# STM32G473 register map
File version: 2.8
CPU: CM4 r0p1, little endian, MPU, FPU, 4 interrupt priority bits
Registers are 32-bit, read-write, reset 0x0 unless marked. A register's access mark holds for its fields unless they carry their own. Offsets are from the block's base; [hi:lo] are bit positions; {n}, {i} and the like mark numbered series; 'fields as' and 'values as' point back to an identical list.

## ADC12_Common — Analog-to-Digital Converter
Base 0x50000300
Same registers: ADC345_Common 0x50000700
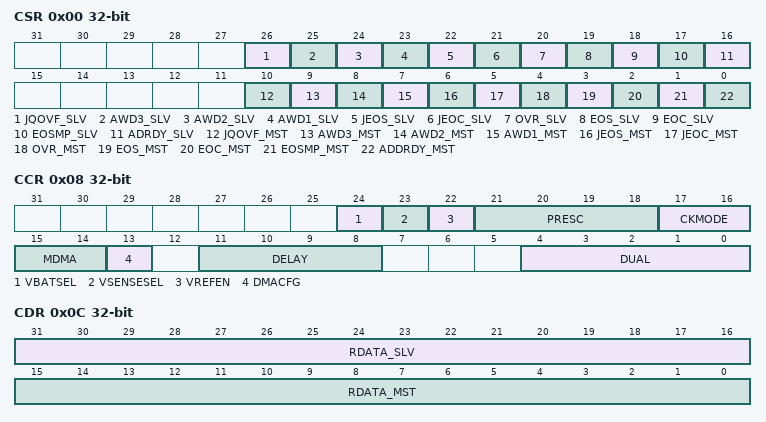
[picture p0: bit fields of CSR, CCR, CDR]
0x00 CSR ro — ADC Common status register
  [26] JQOVF_SLV — Injected Context Queue Overflow flag of the slave ADC
    0=NoOverflow (No injected context queue overflow has occurred); 1=Overflow (Injected context queue overflow has occurred)
  [25] AWD3_SLV — Analog watchdog 3 flag of the slave ADC
    0=NoEvent (No analog watchdog event occurred); 1=Event (Analog watchdog event occurred)
  [24] AWD2_SLV — Analog watchdog 2 flag of the slave ADC
    values as AWD3_SLV
  [23] AWD1_SLV — Analog watchdog 1 flag of the slave ADC
    values as AWD3_SLV
  [22] JEOS_SLV — End of injected sequence flag of the slave ADC
    0=NotComplete (Injected sequence is not complete); 1=Complete (Injected sequence complete)
  [21] JEOC_SLV — End of injected conversion flag of the slave ADC
    0=NotComplete (Injected conversion is not complete); 1=Complete (Injected conversion complete)
  [20] OVR_SLV — Overrun flag of the slave ADC
    0=No overrun occurred; 1=Overrun occurred
  [19] EOS_SLV — End of regular sequence flag of the slave ADC
    0=NotComplete (Regular sequence is not complete); 1=Complete (Regular sequence complete)
  [18] EOC_SLV — End of regular conversion of the slave ADC
    0=NotComplete (Regular conversion is not complete); 1=Complete (Regular conversion complete)
  [17] EOSMP_SLV
    0=NotEnded (End of sampling phase no yet reached); 1=Ended (End of sampling phase reached)
  [16] ADRDY_SLV
    0=NotReady (ADC is not ready to start conversion); 1=Ready (ADC is ready to start conversion)
  [10] JQOVF_MST
    values as JQOVF_SLV
  [9] AWD3_MST
    values as AWD3_SLV
  [8] AWD2_MST
    values as AWD3_SLV
  [7] AWD1_MST
    values as AWD3_SLV
  [6] JEOS_MST
    values as JEOS_SLV
  [5] JEOC_MST
    values as JEOC_SLV
  [4] OVR_MST
    0=No overrun occurred; 1=Overrun occurred
  [3] EOS_MST
    values as EOS_SLV
  [2] EOC_MST
    values as EOC_SLV
  [1] EOSMP_MST
    values as EOSMP_SLV
  [0] ADDRDY_MST
0x08 CCR — ADC common control register
  [24] VBATSEL — VBAT selection
    0=Disabled (V_BAT channel disabled); 1=Enabled (V_BAT channel enabled)
  [23] VSENSESEL — VTS selection
    0=Disabled (Temperature sensor channel disabled); 1=Enabled (Temperature sensor channel enabled)
  [22] VREFEN — VREFINT enable
    0=Disabled (V_REFINT channel disabled); 1=Enabled (V_REFINT channel enabled)
  [21:18] PRESC — ADC prescaler
  [17:16] CKMODE — ADC clock mode
    0=Asynchronous (Use Kernel Clock adc_ker_ck_input divided by PRESC. Asynchronous to AHB clock); 1=SyncDiv1 (Use AHB clock rcc_hclk3. In this case rcc_hclk must equal sys_d1cpre_ck); 2=SyncDiv2 (Use AHB clock rcc_hclk3 divided by 2); 3=SyncDiv4 (Use AHB clock rcc_hclk3 divided by 4)
  [15:14] MDMA — Direct memory access mode for multi ADC mode
  [13] DMACFG — DMA configuration (for multi-ADC mode)
  [11:8] DELAY — Delay between 2 sampling phases
  [4:0] DUAL — Dual ADC mode selection
    0=Independent mode; 1=DualRJ (Dual, combined regular simultaneous + injected simultaneous mode); 2=DualRA (Dual, combined regular simultaneous + alternate trigger mode); 3=DualIJ (Dual, combined interleaved mode + injected simultaneous mode); 5=DualJ (Dual, injected simultaneous mode only); 6=Dual, regular simultaneous mode only; 7=Dual, interleaved mode only; 9=Dual, alternate trigger mode only
0x0C CDR ro — ADC common regular data register for dual and triple modes
  [31:16] RDATA_SLV — Regular data of the slave ADC
  [15:0] RDATA_MST — Regular data of the master ADC

## AES — Advanced encryption standard hardware accelerator
Base 0x50060000
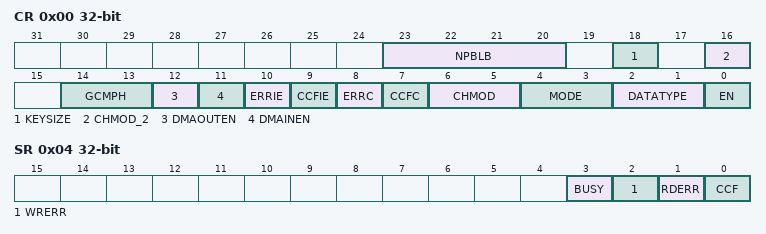
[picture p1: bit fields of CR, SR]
0x00 CR — control register
  [23:20] NPBLB
  [18] KEYSIZE
    0=AES128 (128); 1=AES256 (256)
  [16] CHMOD_2
    0=CHMOD (Mode as per CHMOD (ECB, CBC, CTR, GCM)); 1=CCM (Counter with CBC-MAC (CCM) - CHMOD must be 0 (ECB))
  [14:13] GCMPH
    0=Init phase; 1=Header phase; 2=Payload phase; 3=Final Phase
  [12] DMAOUTEN — Enable DMA management of data output phase
    0=Disable DMA Output; 1=Enabled DMA Output
  [11] DMAINEN — Enable DMA management of data input phase
    0=Disable DMA Input; 1=Enable DMA Input
  [10] ERRIE — Error interrupt enable
    0=Disabled (Disable (mask) error interrupt); 1=Enabled (Enable error interrupt)
  [9] CCFIE — CCF flag interrupt enable
    0=Disabled (Disable (mask) CCF interrupt); 1=Enabled (Enable CCF interrupt)
  [8] ERRC — Error clear
    on write: 1=Clear RDERR and WRERR flags
  [7] CCFC — Computation Complete Flag Clear
    on write: 1=Clear computation complete flag
  [6:5] CHMOD — AES chaining mode
    0=ECB (Electronic codebook (ECB) / Counter with CBC-MAC (CCM) if CHMOD2 is 1); 1=CBC (Cipher-block chaining (CBC)); 2=CTR (Counter mode (CTR)); 3=GCM (Galois counter mode (GCM) and Galois message authentication code (GMAC))
  [4:3] MODE — AES operating mode
    0=Mode 1: encryption; 1=Mode 2: key derivation (or key preparation for ECB/CBC decryption); 2=Mode 3: decryption; 3=Mode 4: key derivation then single decryption
  [2:1] DATATYPE — Data type selection (for data in and data out to/from the cryptographic block)
    0=None (Word); 1=Half-word (16-bit); 2=Byte (8-bit); 3=Bit
  [0] EN — AES enable
    0=Disabled (Disable AES); 1=Enabled (Enable AES)
0x04 SR ro — status register
  [3] BUSY
    0=Idle; 1=Busy
  [2] WRERR — Write error flag
    0=NoError (Write error not detected); 1=Error (Write error detected)
  [1] RDERR — Read error flag
    0=NoError (Read error not detected); 1=Error (Read error detected)
  [0] CCF — Computation complete flag
    0=Complete (Computation complete); 1=NotComplete (Computation not complete)
0x08 DINR — data input register
  [31:0] DIN — Data Input Register
0x0C DOUTR ro — data output register
  [31:0] DOUT — Data output register
0x10 KEYR0 — key register 0
  [31:0] KEY — Data Output Register (LSB key [31:0])
0x14 KEYR1 — key register 1
  [31:0] KEY — AES key register (key [63:32])
0x18 KEYR2 — key register 2
  [31:0] KEY — AES key register (key [95:64])
0x1C KEYR3 — key register 3
  [31:0] KEY — AES key register (MSB key [127:96])
0x20 IVR0 — initialization vector register 0
  [31:0] IVI — initialization vector register (LSB IVR [31:0])
0x24 IVR1 — initialization vector register 1
  [31:0] IVI — Initialization Vector Register (IVR [63:32])
0x28 IVR2 — initialization vector register 2
  [31:0] IVI — Initialization Vector Register (IVR [95:64])
0x2C IVR3 — initialization vector register 3
  [31:0] IVI — Initialization Vector Register (MSB IVR [127:96])
{0x20+4i} KEYR{i} (i=4..7) — key register {i}
  [31:0] KEY — AES key
{0x40+4i} SUSP{i}R (i=0..7) — suspend registers
  [31:0] SUSP — AES suspend
